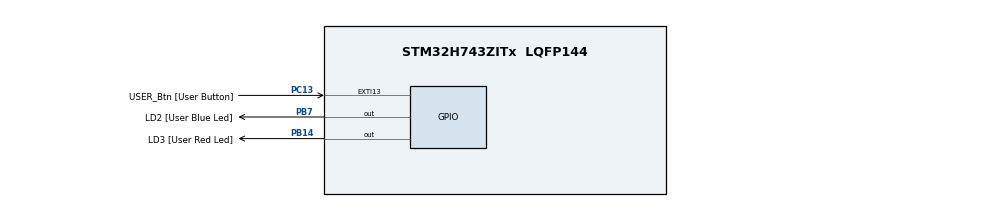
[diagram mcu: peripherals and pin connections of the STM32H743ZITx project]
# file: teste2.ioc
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CORTEX_M7.default_mode_Activation=1
Mcu.Family=STM32H7
Mcu.Name=STM32H743ZITx
Mcu.Package=LQFP144
NVIC.PriorityGroup=NVIC_PRIORITYGROUP_4
PA13\ (JTMS/SWDIO).GPIO_Label=TMS
PA13\ (JTMS/SWDIO).Signal=DEBUG_JTMS-SWDIO
PA14\ (JTCK/SWCLK).GPIO_Label=TCK
PA14\ (JTCK/SWCLK).Signal=DEBUG_JTCK-SWCLK
PB14.GPIO_Label=LD3 [User Red Led]
PB14.Signal=GPIO_Output
PB3\ (JTDO/TRACESWO).GPIO_Label=SWO
PB3\ (JTDO/TRACESWO).Signal=DEBUG_JTDO-SWO
PB7.GPIO_Label=LD2 [User Blue Led]
PB7.Signal=GPIO_Output
PC13.GPIO_Label=USER_Btn [User Button]
PC13.Signal=GPXTI13
PC14-OSC32_IN\ (OSC32_IN).Signal=RCC_OSC32_IN
PC15-OSC32_OUT\ (OSC32_OUT).Signal=RCC_OSC32_OUT
PD8.GPIO_Label=STLK_RX [STM32F103CBT6_PA3]
PD8.Signal=USART3_TX
PD9.GPIO_Label=STLK_TX [STM32F103CBT6_PA2]
PD9.Signal=USART3_RX
ProjectManager.HeapSize=0x200
ProjectManager.StackSize=0x400
ProjectManager.TargetToolchain=STM32CubeIDE
RCC.48MHZClocksFreq_Value=24000000
RCC.ADCFreq_Value=2031746.0317460317
RCC.AHBFreq_Value=216000000
RCC.APB1CLKDivider=RCC_HCLK_DIV4
RCC.APB1Freq_Value=1174603.1746031747
RCC.APB1TimFreq_Value=108000000
RCC.APB2CLKDivider=RCC_HCLK_DIV2
RCC.APB2Freq_Value=1174603.1746031747
RCC.APB2TimFreq_Value=216000000
RCC.APB3Freq_Value=1174603.1746031747
RCC.APB4Freq_Value=1174603.1746031747
RCC.CortexFreq_Value=1174603.1746031747
RCC.DIVM1=63
RCC.DIVM2=63
RCC.DIVM3=63
RCC.DIVN1=148
RCC.DIVN2=4
RCC.DIVN3=4
RCC.DIVP1=128
RCC.DIVQ1=4
RCC.HCLKFreq_Value=1174603.1746031747
RCC.HSE_VALUE=8000000
RCC.HSI_VALUE=64000000
RCC.PLLM=25
RCC.PLLMUL=RCC_PLL_MUL9
RCC.PLLN=432
RCC.PLLQ=9
RCC.PRESCALERUSB=RCC_USBCLKSOURCE_PLL_DIV1_5
RCC.PWR_Regulator_Voltage_Scale=PWR_REGULATOR_VOLTAGE_SCALE1
RCC.SYSCLKFreq_VALUE=1174603.1746031747
RCC.SYSCLKSource=RCC_SYSCLKSOURCE_PLLCLK
RCC.SYSCLKSourceVirtual=RCC_SYSCLKSOURCE_PLLCLK
RCC.USBFreq_Value=37587301.58730159
RCC.VCOOutputFreq_Value=432000000
VP_MEMORYMAP_VS_MEMORYMAP.Mode=CurAppReg
board=NUCLEO-H743ZI

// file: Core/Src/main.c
/* USER CODE BEGIN Header */
/**
  ******************************************************************************
  * @file           : main.c
  * @brief          : Main program body
  ******************************************************************************
  * @attention
  *
  * Copyright (c) 2026 STMicroelectronics.
  * All rights reserved.
  *
  * This software is licensed under terms that can be found in the LICENSE file
  * in the root directory of this software component.
  * If no LICENSE file comes with this software, it is provided AS-IS.
  *
  ******************************************************************************
  */
/* USER CODE END Header */
#include "main.h"

/* USER CODE BEGIN PV */
static volatile uint32_t core_load = 1u;
/* USER CODE END PV */

void SystemClock_Config(void);
static void MPU_Config(void);
static void MX_GPIO_Init(void);

int main(void)
{

  /* MPU Configuration--------------------------------------------------------*/
  MPU_Config();

  /* MCU Configuration--------------------------------------------------------*/

  /* Reset of all peripherals, Initializes the Flash interface and the Systick. */
  HAL_Init();

  /* Configure the system clock */
  SystemClock_Config();

  /* Initialize all configured peripherals */
  MX_GPIO_Init();
  /* USER CODE BEGIN 2 */

  /* --- Baseline current measurement: deactivate everything ---------------- */

  /* Return the pins configured by MX_GPIO_Init to their reset state
     (analog mode, no pull) to minimize leakage. */
  HAL_GPIO_DeInit(GPIOB, LD3_Pin | LD2_Pin);
  HAL_GPIO_DeInit(USER_Btn_GPIO_Port, USER_Btn_Pin);
  HAL_GPIO_DeInit(GPIOD, STLK_RX_Pin | STLK_TX_Pin);

  /* Disable the user-button EXTI interrupt so nothing wakes the core. */
  HAL_NVIC_DisableIRQ(EXTI15_10_IRQn);

  /* Gate all GPIO port clocks that were enabled. */
  __HAL_RCC_GPIOA_CLK_DISABLE();
  __HAL_RCC_GPIOB_CLK_DISABLE();
  __HAL_RCC_GPIOC_CLK_DISABLE();
  __HAL_RCC_GPIOD_CLK_DISABLE();

  /* Stop the SysTick tick interrupt (no HAL_Delay is used). */
  HAL_SuspendTick();

  /* USER CODE END 2 */

  /* Infinite loop */
  while (1)
  {

    /* USER CODE BEGIN 3 */
    /* Keep the CPU in Run mode with continuous ALU work so the measurement
       reflects full active core power (volatile prevents optimizing it away). */
    core_load = core_load * 1664525u + 1013904223u;
  }
  /* USER CODE END 3 */
}

void SystemClock_Config(void)
{
  RCC_OscInitTypeDef RCC_OscInitStruct = {0};
  RCC_ClkInitTypeDef RCC_ClkInitStruct = {0};

  /** Supply configuration update enable
  */
  HAL_PWREx_ConfigSupply(PWR_LDO_SUPPLY);

  /** Configure the main internal regulator output voltage
  */
  __HAL_PWR_VOLTAGESCALING_CONFIG(PWR_REGULATOR_VOLTAGE_SCALE1);

  while(!__HAL_PWR_GET_FLAG(PWR_FLAG_VOSRDY)) {}

  /** Initializes the RCC Oscillators according to the specified parameters
  * in the RCC_OscInitTypeDef structure.
  */
  RCC_OscInitStruct.OscillatorType = RCC_OSCILLATORTYPE_HSI;
  RCC_OscInitStruct.HSIState = RCC_HSI_DIV1;
  RCC_OscInitStruct.HSICalibrationValue = RCC_HSICALIBRATION_DEFAULT;
  RCC_OscInitStruct.PLL.PLLState = RCC_PLL_ON;
  RCC_OscInitStruct.PLL.PLLSource = RCC_PLLSOURCE_HSI;
  RCC_OscInitStruct.PLL.PLLM = 63;
  RCC_OscInitStruct.PLL.PLLN = 148;
  RCC_OscInitStruct.PLL.PLLP = 128;
  RCC_OscInitStruct.PLL.PLLQ = 4;
  RCC_OscInitStruct.PLL.PLLR = 2;
  RCC_OscInitStruct.PLL.PLLRGE = RCC_PLL1VCIRANGE_0;
  RCC_OscInitStruct.PLL.PLLVCOSEL = RCC_PLL1VCOMEDIUM;
  RCC_OscInitStruct.PLL.PLLFRACN = 0;
  if (HAL_RCC_OscConfig(&RCC_OscInitStruct) != HAL_OK)
  {
    Error_Handler();
  }

  /** Initializes the CPU, AHB and APB buses clocks
  */
  RCC_ClkInitStruct.ClockType = RCC_CLOCKTYPE_HCLK|RCC_CLOCKTYPE_SYSCLK
                              |RCC_CLOCKTYPE_PCLK1|RCC_CLOCKTYPE_PCLK2
                              |RCC_CLOCKTYPE_D3PCLK1|RCC_CLOCKTYPE_D1PCLK1;
  RCC_ClkInitStruct.SYSCLKSource = RCC_SYSCLKSOURCE_PLLCLK;
  RCC_ClkInitStruct.SYSCLKDivider = RCC_SYSCLK_DIV1;
  RCC_ClkInitStruct.AHBCLKDivider = RCC_HCLK_DIV1;
  RCC_ClkInitStruct.APB3CLKDivider = RCC_APB3_DIV1;
  RCC_ClkInitStruct.APB1CLKDivider = RCC_APB1_DIV1;
  RCC_ClkInitStruct.APB2CLKDivider = RCC_APB2_DIV1;
  RCC_ClkInitStruct.APB4CLKDivider = RCC_APB4_DIV1;

  if (HAL_RCC_ClockConfig(&RCC_ClkInitStruct, FLASH_LATENCY_0) != HAL_OK)
  {
    Error_Handler();
  }
}

static void MX_GPIO_Init(void)
{
  GPIO_InitTypeDef GPIO_InitStruct = {0};

  /* GPIO Ports Clock Enable */
  __HAL_RCC_GPIOC_CLK_ENABLE();
  __HAL_RCC_GPIOB_CLK_ENABLE();
  __HAL_RCC_GPIOD_CLK_ENABLE();
  __HAL_RCC_GPIOA_CLK_ENABLE();

  /*Configure GPIO pin Output Level */
  HAL_GPIO_WritePin(GPIOB, LD3_Pin|LD2_Pin, GPIO_PIN_RESET);

  /*Configure GPIO pin : USER_Btn_Pin */
  GPIO_InitStruct.Pin = USER_Btn_Pin;
  GPIO_InitStruct.Mode = GPIO_MODE_IT_RISING;
  GPIO_InitStruct.Pull = GPIO_NOPULL;
  HAL_GPIO_Init(USER_Btn_GPIO_Port, &GPIO_InitStruct);

  /*Configure GPIO pins : LD3_Pin LD2_Pin */
  GPIO_InitStruct.Pin = LD3_Pin|LD2_Pin;
  GPIO_InitStruct.Mode = GPIO_MODE_OUTPUT_PP;
  GPIO_InitStruct.Pull = GPIO_NOPULL;
  GPIO_InitStruct.Speed = GPIO_SPEED_FREQ_LOW;
  HAL_GPIO_Init(GPIOB, &GPIO_InitStruct);

  /*Configure GPIO pins : STLK_RX_Pin STLK_TX_Pin */
  GPIO_InitStruct.Pin = STLK_RX_Pin|STLK_TX_Pin;
  GPIO_InitStruct.Mode = GPIO_MODE_AF_PP;
  GPIO_InitStruct.Pull = GPIO_NOPULL;
  GPIO_InitStruct.Speed = GPIO_SPEED_FREQ_LOW;
  GPIO_InitStruct.Alternate = GPIO_AF7_USART3;
  HAL_GPIO_Init(GPIOD, &GPIO_InitStruct);

}

 /* MPU Configuration */

void MPU_Config(void)
{
  MPU_Region_InitTypeDef MPU_InitStruct = {0};

  /* Disables the MPU */
  HAL_MPU_Disable();

  /** Initializes and configures the Region and the memory to be protected
  */
  MPU_InitStruct.Enable = MPU_REGION_ENABLE;
  MPU_InitStruct.Number = MPU_REGION_NUMBER0;
  MPU_InitStruct.BaseAddress = 0x0;
  MPU_InitStruct.Size = MPU_REGION_SIZE_4GB;
  MPU_InitStruct.SubRegionDisable = 0x87;
  MPU_InitStruct.TypeExtField = MPU_TEX_LEVEL0;
  MPU_InitStruct.AccessPermission = MPU_REGION_NO_ACCESS;
  MPU_InitStruct.DisableExec = MPU_INSTRUCTION_ACCESS_DISABLE;
  MPU_InitStruct.IsShareable = MPU_ACCESS_SHAREABLE;
  MPU_InitStruct.IsCacheable = MPU_ACCESS_NOT_CACHEABLE;
  MPU_InitStruct.IsBufferable = MPU_ACCESS_NOT_BUFFERABLE;

  HAL_MPU_ConfigRegion(&MPU_InitStruct);
  /* Enables the MPU */
  HAL_MPU_Enable(MPU_PRIVILEGED_DEFAULT);

}

void Error_Handler(void)
{
  __disable_irq();
  while (1)
  {
  }
}
